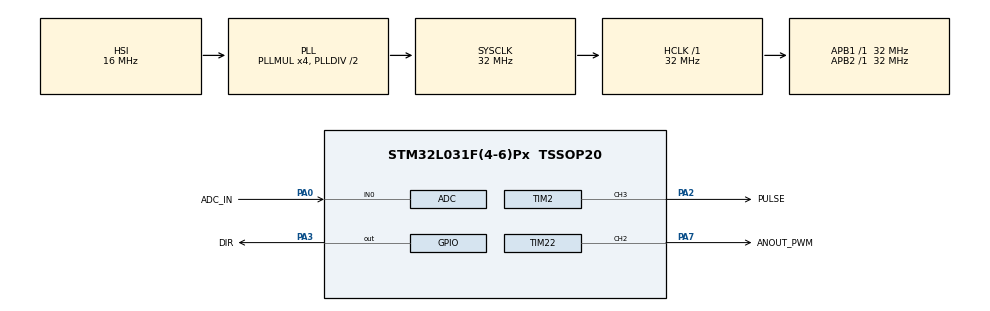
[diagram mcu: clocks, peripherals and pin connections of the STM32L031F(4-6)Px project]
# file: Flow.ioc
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ADC.ClockPrescaler=ADC_CLOCK_SYNC_PCLK_DIV2
ADC.DMAContinuousRequests=ENABLE
ADC.ExternalTrigConv=ADC_EXTERNALTRIGCONV_T21_CC2
ADC.ExternalTrigConvEdge=ADC_EXTERNALTRIGCONVEDGE_FALLING
ADC.Overrun=ADC_OVR_DATA_OVERWRITTEN
ADC.OversamplingMode=DISABLE
ADC.SamplingTime=ADC_SAMPLETIME_7CYCLES_5
Dma.ADC.0.Direction=DMA_PERIPH_TO_MEMORY
Dma.ADC.0.Instance=DMA1_Channel1
Dma.ADC.0.MemDataAlignment=DMA_MDATAALIGN_HALFWORD
Dma.ADC.0.MemInc=DMA_MINC_ENABLE
Dma.ADC.0.Mode=DMA_CIRCULAR
Dma.ADC.0.PeriphDataAlignment=DMA_PDATAALIGN_HALFWORD
Dma.ADC.0.PeriphInc=DMA_PINC_DISABLE
Dma.ADC.0.Priority=DMA_PRIORITY_HIGH
Dma.Request0=ADC
Mcu.Family=STM32L0
Mcu.Name=STM32L031F(4-6)Px
Mcu.Package=TSSOP20
Mcu.UserConstants=SYS_FREQ,32000000;US_FREQ,40000;SAMPLES_PER_CYCLE,4;TIM2_RELOAD,((((SYS_FREQ/US_FREQ)/SAMPLES_PER_CYCLE)*SAMPLES_PER_CYCLE)-1);TIM21_RELOAD,(SYS_FREQ/(SAMPLES_PER_CYCLE*US_FREQ)-1);TIM2_CH3_PULSE,(TIM2_RELOAD/2);TIM21_CH2_PULSE,(TIM21_RELOAD/2);ANOUT_RESOLUTION,1024;TIM22_RELOAD,(ANOUT_RESOLUTION-1);DEAD_SAMPLES,0;SAMPLES_PER_PHASE_MEASUREMENT,400
NVIC.DMA1_Channel1_IRQn=true\:0\:0\:false\:false\:true\:false\:true
PA0-CK_IN.GPIO_Label=ADC_IN
PA0-CK_IN.Mode=IN0
PA0-CK_IN.Signal=ADC_IN0
PA13.Mode=Serial_Wire
PA13.Signal=SYS_SWDIO
PA14.Mode=Serial_Wire
PA14.Signal=SYS_SWCLK
PA2.GPIO_Label=PULSE
PA2.GPIO_ModeDefaultPP=GPIO_MODE_AF_PP
PA2.GPIO_Speed=GPIO_SPEED_FREQ_MEDIUM
PA2.Signal=S_TIM2_CH3
PA3.GPIO_Label=DIR
PA3.GPIO_ModeDefaultOutputPP=GPIO_MODE_OUTPUT_PP
PA3.GPIO_Speed=GPIO_SPEED_FREQ_MEDIUM
PA3.Signal=GPIO_Output
PA7.GPIO_Label=ANOUT_PWM
PA7.GPIO_Speed=GPIO_SPEED_FREQ_MEDIUM
PA7.Signal=S_TIM22_CH2
ProjectManager.HeapSize=0x200
ProjectManager.StackSize=0x400
ProjectManager.TargetToolchain=Makefile
RCC.AHBFreq_Value=32000000
RCC.APB1Freq_Value=32000000
RCC.APB1TimFreq_Value=32000000
RCC.APB2Freq_Value=32000000
RCC.APB2TimFreq_Value=32000000
RCC.HCLKFreq_Value=32000000
RCC.HSE_VALUE=8000000
RCC.HSI16_VALUE=16000000
RCC.HSI_VALUE=16000000
RCC.LSE_VALUE=32768
RCC.MSI_VALUE=2097000
RCC.PLLMUL=RCC_PLLMUL_4
RCC.SYSCLKFreq_VALUE=32000000
RCC.SYSCLKSource=RCC_SYSCLKSOURCE_PLLCLK
RCC.VCOOutputFreq_Value=64000000
SH.S_TIM22_CH2.0=TIM22_CH2,PWM Generation2 CH2
SH.S_TIM2_CH3.0=TIM2_CH3,PWM Generation3 CH3
TIM2.Channel-PWM\ Generation3\ CH3=TIM_CHANNEL_3
TIM2.Period=TIM2_RELOAD
TIM2.Pulse-PWM\ Generation3\ CH3=TIM2_CH3_PULSE
TIM2.TIM_MasterOutputTrigger=TIM_TRGO_ENABLE
TIM2.TIM_MasterSlaveMode=TIM_MASTERSLAVEMODE_DISABLE
TIM21.Channel-PWM\ Generation2\ No\ Output=TIM_CHANNEL_2
TIM21.OC2Preload_PWM=DISABLE
TIM21.Period=TIM21_RELOAD
TIM21.Pulse-PWM\ Generation2\ No\ Output=TIM21_CH2_PULSE
TIM21.TIM_MasterOutputTrigger=TIM_TRGO_OC2REF
TIM21.TIM_MasterSlaveMode=TIM_MASTERSLAVEMODE_DISABLE
TIM22.Channel-PWM\ Generation2\ CH2=TIM_CHANNEL_2
TIM22.OC2Preload_PWM=DISABLE
TIM22.Period=TIM22_RELOAD
TIM22.Pulse-PWM\ Generation2\ CH2=(TIM22_RELOAD/2)
VP_TIM21_VS_ClockSourceINT.Mode=Internal
VP_TIM21_VS_ClockSourceITR.Mode=TriggerSource_ITR0
VP_TIM21_VS_ControllerModeGated.Mode=Gated Mode
VP_TIM21_VS_no_output2.Mode=PWM Generation2 No Output
VP_TIM2_VS_ClockSourceINT.Mode=Internal
board=custom

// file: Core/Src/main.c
/* USER CODE BEGIN Header */
/**
  ******************************************************************************
  * @file           : main.c
  * @brief          : Main program body
  ******************************************************************************
  * @attention
  *
  * <h2><center>&copy; Copyright (c) 2021 STMicroelectronics.
  * All rights reserved.</center></h2>
  *
  * This software component is licensed by ST under BSD 3-Clause license,
  * the "License"; You may not use this file except in compliance with the
  * License. You may obtain a copy of the License at:
  *                        opensource.org/licenses/BSD-3-Clause
  *
  ******************************************************************************
  */
/* USER CODE END Header */
#include "main.h"

/* USER CODE BEGIN Includes */
#include "flow.h"
/* USER CODE END Includes */

ADC_HandleTypeDef hadc;
DMA_HandleTypeDef hdma_adc;

TIM_HandleTypeDef htim2;
TIM_HandleTypeDef htim21;
TIM_HandleTypeDef htim22;

void SystemClock_Config(void);
static void MX_GPIO_Init(void);
static void MX_DMA_Init(void);
static void MX_ADC_Init(void);
static void MX_TIM2_Init(void);
static void MX_TIM21_Init(void);
static void MX_TIM22_Init(void);

int main(void)
{

  /* MCU Configuration--------------------------------------------------------*/

  /* Reset of all peripherals, Initializes the Flash interface and the Systick. */
  HAL_Init();

  /* USER CODE BEGIN Init */
	Flow_Init();
  /* USER CODE END Init */

  /* Configure the system clock */
  SystemClock_Config();

  /* Initialize all configured peripherals */
  MX_GPIO_Init();
  MX_DMA_Init();
  MX_ADC_Init();
  MX_TIM2_Init();
  MX_TIM21_Init();
  MX_TIM22_Init();
  /* USER CODE BEGIN 2 */
  Flow_Start();
  /* USER CODE END 2 */

  /* Infinite loop */
  while (1)
  {

  }
}

void SystemClock_Config(void)
{
  RCC_OscInitTypeDef RCC_OscInitStruct = {0};
  RCC_ClkInitTypeDef RCC_ClkInitStruct = {0};

  /** Configure the main internal regulator output voltage
  */
  __HAL_PWR_VOLTAGESCALING_CONFIG(PWR_REGULATOR_VOLTAGE_SCALE1);
  /** Initializes the RCC Oscillators according to the specified parameters
  * in the RCC_OscInitTypeDef structure.
  */
  RCC_OscInitStruct.OscillatorType = RCC_OSCILLATORTYPE_HSI;
  RCC_OscInitStruct.HSIState = RCC_HSI_ON;
  RCC_OscInitStruct.HSICalibrationValue = RCC_HSICALIBRATION_DEFAULT;
  RCC_OscInitStruct.PLL.PLLState = RCC_PLL_ON;
  RCC_OscInitStruct.PLL.PLLSource = RCC_PLLSOURCE_HSI;
  RCC_OscInitStruct.PLL.PLLMUL = RCC_PLLMUL_4;
  RCC_OscInitStruct.PLL.PLLDIV = RCC_PLLDIV_2;
  if (HAL_RCC_OscConfig(&RCC_OscInitStruct) != HAL_OK)
  {
    Error_Handler();
  }
  /** Initializes the CPU, AHB and APB buses clocks
  */
  RCC_ClkInitStruct.ClockType = RCC_CLOCKTYPE_HCLK|RCC_CLOCKTYPE_SYSCLK
                              |RCC_CLOCKTYPE_PCLK1|RCC_CLOCKTYPE_PCLK2;
  RCC_ClkInitStruct.SYSCLKSource = RCC_SYSCLKSOURCE_PLLCLK;
  RCC_ClkInitStruct.AHBCLKDivider = RCC_SYSCLK_DIV1;
  RCC_ClkInitStruct.APB1CLKDivider = RCC_HCLK_DIV1;
  RCC_ClkInitStruct.APB2CLKDivider = RCC_HCLK_DIV1;

  if (HAL_RCC_ClockConfig(&RCC_ClkInitStruct, FLASH_LATENCY_1) != HAL_OK)
  {
    Error_Handler();
  }
}

static void MX_ADC_Init(void)
{

  ADC_ChannelConfTypeDef sConfig = {0};

  /** Configure the global features of the ADC (Clock, Resolution, Data Alignment and number of conversion)
  */
  hadc.Instance = ADC1;
  hadc.Init.OversamplingMode = DISABLE;
  hadc.Init.ClockPrescaler = ADC_CLOCK_SYNC_PCLK_DIV2;
  hadc.Init.Resolution = ADC_RESOLUTION_12B;
  hadc.Init.SamplingTime = ADC_SAMPLETIME_7CYCLES_5;
  hadc.Init.ScanConvMode = ADC_SCAN_DIRECTION_FORWARD;
  hadc.Init.DataAlign = ADC_DATAALIGN_RIGHT;
  hadc.Init.ContinuousConvMode = DISABLE;
  hadc.Init.DiscontinuousConvMode = DISABLE;
  hadc.Init.ExternalTrigConvEdge = ADC_EXTERNALTRIGCONVEDGE_FALLING;
  hadc.Init.ExternalTrigConv = ADC_EXTERNALTRIGCONV_T21_CC2;
  hadc.Init.DMAContinuousRequests = ENABLE;
  hadc.Init.EOCSelection = ADC_EOC_SINGLE_CONV;
  hadc.Init.Overrun = ADC_OVR_DATA_OVERWRITTEN;
  hadc.Init.LowPowerAutoWait = DISABLE;
  hadc.Init.LowPowerFrequencyMode = DISABLE;
  hadc.Init.LowPowerAutoPowerOff = DISABLE;
  if (HAL_ADC_Init(&hadc) != HAL_OK)
  {
    Error_Handler();
  }
  /** Configure for the selected ADC regular channel to be converted.
  */
  sConfig.Channel = ADC_CHANNEL_0;
  sConfig.Rank = ADC_RANK_CHANNEL_NUMBER;
  if (HAL_ADC_ConfigChannel(&hadc, &sConfig) != HAL_OK)
  {
    Error_Handler();
  }

}

static void MX_TIM2_Init(void)
{

  TIM_ClockConfigTypeDef sClockSourceConfig = {0};
  TIM_MasterConfigTypeDef sMasterConfig = {0};
  TIM_OC_InitTypeDef sConfigOC = {0};

  htim2.Instance = TIM2;
  htim2.Init.Prescaler = 0;
  htim2.Init.CounterMode = TIM_COUNTERMODE_UP;
  htim2.Init.Period = TIM2_RELOAD;
  htim2.Init.ClockDivision = TIM_CLOCKDIVISION_DIV1;
  htim2.Init.AutoReloadPreload = TIM_AUTORELOAD_PRELOAD_DISABLE;
  if (HAL_TIM_Base_Init(&htim2) != HAL_OK)
  {
    Error_Handler();
  }
  sClockSourceConfig.ClockSource = TIM_CLOCKSOURCE_INTERNAL;
  if (HAL_TIM_ConfigClockSource(&htim2, &sClockSourceConfig) != HAL_OK)
  {
    Error_Handler();
  }
  if (HAL_TIM_PWM_Init(&htim2) != HAL_OK)
  {
    Error_Handler();
  }
  sMasterConfig.MasterOutputTrigger = TIM_TRGO_ENABLE;
  sMasterConfig.MasterSlaveMode = TIM_MASTERSLAVEMODE_DISABLE;
  if (HAL_TIMEx_MasterConfigSynchronization(&htim2, &sMasterConfig) != HAL_OK)
  {
    Error_Handler();
  }
  sConfigOC.OCMode = TIM_OCMODE_PWM1;
  sConfigOC.Pulse = TIM2_CH3_PULSE;
  sConfigOC.OCPolarity = TIM_OCPOLARITY_HIGH;
  sConfigOC.OCFastMode = TIM_OCFAST_DISABLE;
  if (HAL_TIM_PWM_ConfigChannel(&htim2, &sConfigOC, TIM_CHANNEL_3) != HAL_OK)
  {
    Error_Handler();
  }
  HAL_TIM_MspPostInit(&htim2);

}

static void MX_TIM21_Init(void)
{

  TIM_ClockConfigTypeDef sClockSourceConfig = {0};
  TIM_SlaveConfigTypeDef sSlaveConfig = {0};
  TIM_MasterConfigTypeDef sMasterConfig = {0};
  TIM_OC_InitTypeDef sConfigOC = {0};

  htim21.Instance = TIM21;
  htim21.Init.Prescaler = 0;
  htim21.Init.CounterMode = TIM_COUNTERMODE_UP;
  htim21.Init.Period = TIM21_RELOAD;
  htim21.Init.ClockDivision = TIM_CLOCKDIVISION_DIV1;
  htim21.Init.AutoReloadPreload = TIM_AUTORELOAD_PRELOAD_DISABLE;
  if (HAL_TIM_Base_Init(&htim21) != HAL_OK)
  {
    Error_Handler();
  }
  sClockSourceConfig.ClockSource = TIM_CLOCKSOURCE_INTERNAL;
  if (HAL_TIM_ConfigClockSource(&htim21, &sClockSourceConfig) != HAL_OK)
  {
    Error_Handler();
  }
  if (HAL_TIM_PWM_Init(&htim21) != HAL_OK)
  {
    Error_Handler();
  }
  sSlaveConfig.SlaveMode = TIM_SLAVEMODE_GATED;
  sSlaveConfig.InputTrigger = TIM_TS_ITR0;
  if (HAL_TIM_SlaveConfigSynchro(&htim21, &sSlaveConfig) != HAL_OK)
  {
    Error_Handler();
  }
  sMasterConfig.MasterOutputTrigger = TIM_TRGO_OC2REF;
  sMasterConfig.MasterSlaveMode = TIM_MASTERSLAVEMODE_DISABLE;
  if (HAL_TIMEx_MasterConfigSynchronization(&htim21, &sMasterConfig) != HAL_OK)
  {
    Error_Handler();
  }
  sConfigOC.OCMode = TIM_OCMODE_PWM1;
  sConfigOC.Pulse = TIM21_CH2_PULSE;
  sConfigOC.OCPolarity = TIM_OCPOLARITY_HIGH;
  sConfigOC.OCFastMode = TIM_OCFAST_DISABLE;
  if (HAL_TIM_PWM_ConfigChannel(&htim21, &sConfigOC, TIM_CHANNEL_2) != HAL_OK)
  {
    Error_Handler();
  }
  __HAL_TIM_DISABLE_OCxPRELOAD(&htim21, TIM_CHANNEL_2);

}

static void MX_TIM22_Init(void)
{

  TIM_MasterConfigTypeDef sMasterConfig = {0};
  TIM_OC_InitTypeDef sConfigOC = {0};

  htim22.Instance = TIM22;
  htim22.Init.Prescaler = 0;
  htim22.Init.CounterMode = TIM_COUNTERMODE_UP;
  htim22.Init.Period = TIM22_RELOAD;
  htim22.Init.ClockDivision = TIM_CLOCKDIVISION_DIV1;
  htim22.Init.AutoReloadPreload = TIM_AUTORELOAD_PRELOAD_DISABLE;
  if (HAL_TIM_PWM_Init(&htim22) != HAL_OK)
  {
    Error_Handler();
  }
  sMasterConfig.MasterOutputTrigger = TIM_TRGO_RESET;
  sMasterConfig.MasterSlaveMode = TIM_MASTERSLAVEMODE_DISABLE;
  if (HAL_TIMEx_MasterConfigSynchronization(&htim22, &sMasterConfig) != HAL_OK)
  {
    Error_Handler();
  }
  sConfigOC.OCMode = TIM_OCMODE_PWM1;
  sConfigOC.Pulse = (TIM22_RELOAD/2);
  sConfigOC.OCPolarity = TIM_OCPOLARITY_HIGH;
  sConfigOC.OCFastMode = TIM_OCFAST_DISABLE;
  if (HAL_TIM_PWM_ConfigChannel(&htim22, &sConfigOC, TIM_CHANNEL_2) != HAL_OK)
  {
    Error_Handler();
  }
  __HAL_TIM_DISABLE_OCxPRELOAD(&htim22, TIM_CHANNEL_2);
  HAL_TIM_MspPostInit(&htim22);

}

static void MX_DMA_Init(void)
{

  /* DMA controller clock enable */
  __HAL_RCC_DMA1_CLK_ENABLE();

  /* DMA interrupt init */
  /* DMA1_Channel1_IRQn interrupt configuration */
  HAL_NVIC_SetPriority(DMA1_Channel1_IRQn, 0, 0);
  HAL_NVIC_EnableIRQ(DMA1_Channel1_IRQn);

}

static void MX_GPIO_Init(void)
{
  GPIO_InitTypeDef GPIO_InitStruct = {0};

  /* GPIO Ports Clock Enable */
  __HAL_RCC_GPIOA_CLK_ENABLE();

  /*Configure GPIO pin Output Level */
  HAL_GPIO_WritePin(DIR_GPIO_Port, DIR_Pin, GPIO_PIN_RESET);

  /*Configure GPIO pin : DIR_Pin */
  GPIO_InitStruct.Pin = DIR_Pin;
  GPIO_InitStruct.Mode = GPIO_MODE_OUTPUT_PP;
  GPIO_InitStruct.Pull = GPIO_NOPULL;
  GPIO_InitStruct.Speed = GPIO_SPEED_FREQ_MEDIUM;
  HAL_GPIO_Init(DIR_GPIO_Port, &GPIO_InitStruct);

}

void Error_Handler(void)
{
  __disable_irq();
  while (1)
  {
  }
}

/************************ (C) COPYRIGHT STMicroelectronics *****END OF FILE****/
